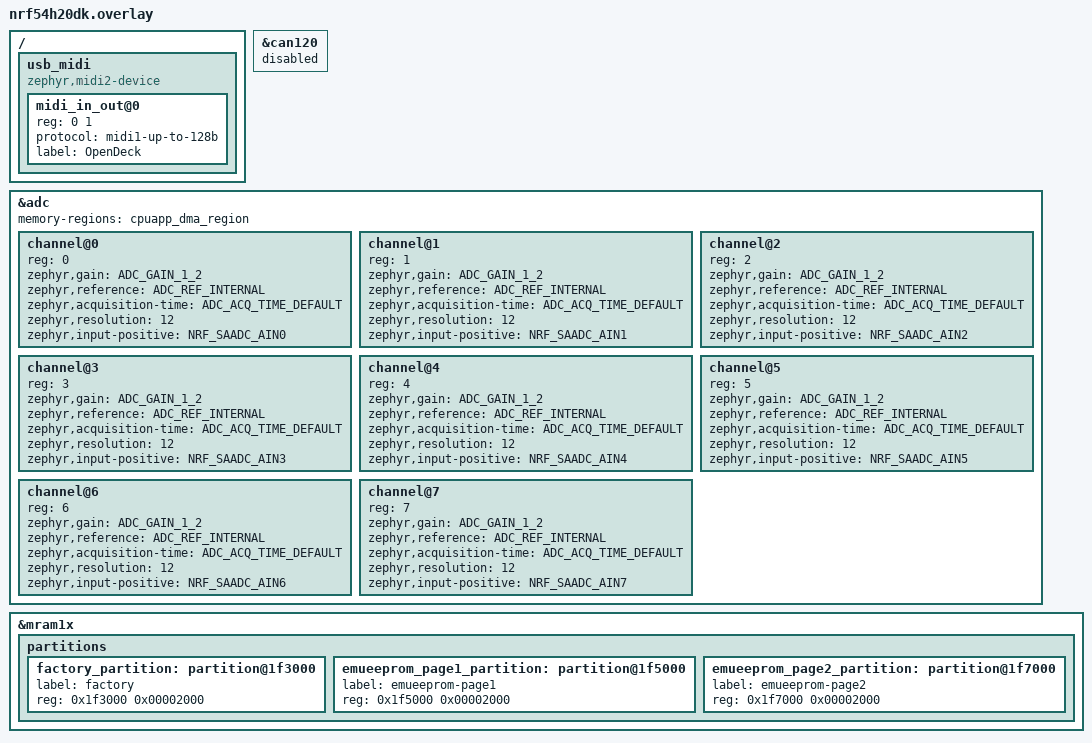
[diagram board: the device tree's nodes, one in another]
/ {
    usb_midi: usb_midi {
        compatible = "zephyr,midi2-device";
        status = "okay";
        #address-cells = <1>;
        #size-cells = <1>;

        midi_in_out@0 {
            reg = <0 1>;
            protocol = "midi1-up-to-128b";
            label = "OpenDeck";
        };
    };
};

&can120 {
    status = "disabled";
};

&adc {
    #address-cells = <1>;
    #size-cells = <0>;
    status = "okay";
    memory-regions = <&cpuapp_dma_region>;

    channel@0 {
        reg = <0>;
        zephyr,gain = "ADC_GAIN_1_2";
        zephyr,reference = "ADC_REF_INTERNAL";
        zephyr,acquisition-time = <ADC_ACQ_TIME_DEFAULT>;
        zephyr,resolution = <12>;
        zephyr,input-positive = <NRF_SAADC_AIN0>;
    };

    channel@1 {
        reg = <1>;
        zephyr,gain = "ADC_GAIN_1_2";
        zephyr,reference = "ADC_REF_INTERNAL";
        zephyr,acquisition-time = <ADC_ACQ_TIME_DEFAULT>;
        zephyr,resolution = <12>;
        zephyr,input-positive = <NRF_SAADC_AIN1>;
    };

    channel@2 {
        reg = <2>;
        zephyr,gain = "ADC_GAIN_1_2";
        zephyr,reference = "ADC_REF_INTERNAL";
        zephyr,acquisition-time = <ADC_ACQ_TIME_DEFAULT>;
        zephyr,resolution = <12>;
        zephyr,input-positive = <NRF_SAADC_AIN2>;
    };

    channel@3 {
        reg = <3>;
        zephyr,gain = "ADC_GAIN_1_2";
        zephyr,reference = "ADC_REF_INTERNAL";
        zephyr,acquisition-time = <ADC_ACQ_TIME_DEFAULT>;
        zephyr,resolution = <12>;
        zephyr,input-positive = <NRF_SAADC_AIN3>;
    };

    channel@4 {
        reg = <4>;
        zephyr,gain = "ADC_GAIN_1_2";
        zephyr,reference = "ADC_REF_INTERNAL";
        zephyr,acquisition-time = <ADC_ACQ_TIME_DEFAULT>;
        zephyr,resolution = <12>;
        zephyr,input-positive = <NRF_SAADC_AIN4>;
    };

    channel@5 {
        reg = <5>;
        zephyr,gain = "ADC_GAIN_1_2";
        zephyr,reference = "ADC_REF_INTERNAL";
        zephyr,acquisition-time = <ADC_ACQ_TIME_DEFAULT>;
        zephyr,resolution = <12>;
        zephyr,input-positive = <NRF_SAADC_AIN5>;
    };

    channel@6 {
        reg = <6>;
        zephyr,gain = "ADC_GAIN_1_2";
        zephyr,reference = "ADC_REF_INTERNAL";
        zephyr,acquisition-time = <ADC_ACQ_TIME_DEFAULT>;
        zephyr,resolution = <12>;
        zephyr,input-positive = <NRF_SAADC_AIN6>;
    };

    channel@7 {
        reg = <7>;
        zephyr,gain = "ADC_GAIN_1_2";
        zephyr,reference = "ADC_REF_INTERNAL";
        zephyr,acquisition-time = <ADC_ACQ_TIME_DEFAULT>;
        zephyr,resolution = <12>;
        zephyr,input-positive = <NRF_SAADC_AIN7>;
    };

};

&mram1x {
    partitions {
        factory_partition: partition@1f3000 {
            label = "factory";
            reg = <0x1f3000 0x00002000>;
        };

        emueeprom_page1_partition: partition@1f5000 {
            label = "emueeprom-page1";
            reg = <0x1f5000 0x00002000>;
        };

        emueeprom_page2_partition: partition@1f7000 {
            label = "emueeprom-page2";
            reg = <0x1f7000 0x00002000>;
        };
    };
};
